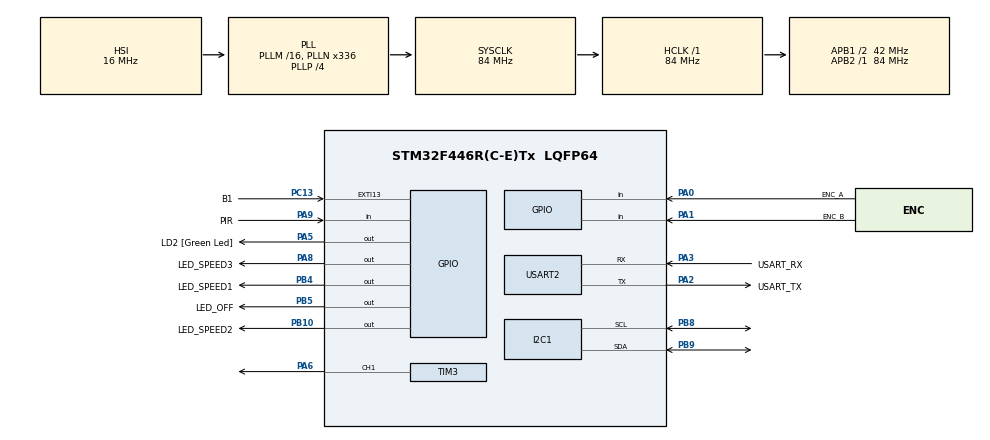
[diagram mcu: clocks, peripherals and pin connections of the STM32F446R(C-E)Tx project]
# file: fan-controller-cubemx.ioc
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Dma.Request0=USART2_TX
Dma.USART2_TX.0.Direction=DMA_MEMORY_TO_PERIPH
Dma.USART2_TX.0.FIFOMode=DMA_FIFOMODE_DISABLE
Dma.USART2_TX.0.Instance=DMA1_Stream6
Dma.USART2_TX.0.MemDataAlignment=DMA_MDATAALIGN_BYTE
Dma.USART2_TX.0.MemInc=DMA_MINC_ENABLE
Dma.USART2_TX.0.Mode=DMA_NORMAL
Dma.USART2_TX.0.PeriphDataAlignment=DMA_PDATAALIGN_BYTE
Dma.USART2_TX.0.PeriphInc=DMA_PINC_DISABLE
Dma.USART2_TX.0.Priority=DMA_PRIORITY_LOW
FREERTOS.Tasks01=defaultTask,24,128,StartDefaultTask,Default,NULL,Dynamic,NULL,NULL
FREERTOS.configUSE_NEWLIB_REENTRANT=1
Mcu.Family=STM32F4
Mcu.Name=STM32F446R(C-E)Tx
Mcu.Package=LQFP64
NVIC.DMA1_Stream6_IRQn=true\:5\:0\:false\:false\:true\:true\:false\:true\:true
NVIC.EXTI15_10_IRQn=true\:5\:0\:false\:false\:true\:true\:true\:true\:true
NVIC.PriorityGroup=NVIC_PRIORITYGROUP_4
NVIC.TIM1_TRG_COM_TIM11_IRQn=true\:15\:0\:false\:false\:true\:false\:false\:true\:true
NVIC.TIM2_IRQn=true\:5\:0\:false\:false\:true\:true\:true\:true\:true
NVIC.TimeBase=TIM1_TRG_COM_TIM11_IRQn
NVIC.TimeBaseIP=TIM11
NVIC.USART2_IRQn=true\:5\:0\:false\:false\:true\:true\:true\:true\:true
PA0-WKUP.GPIO_Label=ENC_A
PA0-WKUP.GPIO_PuPd=GPIO_PULLUP
PA0-WKUP.Signal=GPIO_Input
PA1.GPIO_Label=ENC_B
PA1.GPIO_PuPd=GPIO_PULLUP
PA1.Signal=GPIO_Input
PA13.Signal=SYS_JTMS-SWDIO
PA14.GPIO_Label=TCK
PA14.Signal=SYS_JTCK-SWCLK
PA2.GPIO_Label=USART_TX
PA2.Mode=Asynchronous
PA2.Signal=USART2_TX
PA3.GPIO_Label=USART_RX
PA3.Mode=Asynchronous
PA3.Signal=USART2_RX
PA5.GPIO_Label=LD2 [Green Led]
PA5.Signal=GPIO_Output
PA6.Signal=S_TIM3_CH1
PA8.GPIO_Label=LED_SPEED3
PA8.Signal=GPIO_Output
PA9.GPIO_Label=PIR
PA9.GPIO_PuPd=GPIO_PULLDOWN
PA9.Signal=GPIO_Input
PB10.GPIO_Label=LED_SPEED2
PB10.Signal=GPIO_Output
PB3.GPIO_Label=SWO
PB3.Signal=SYS_JTDO-SWO
PB4.GPIO_Label=LED_SPEED1
PB4.Signal=GPIO_Output
PB5.GPIO_Label=LED_OFF
PB5.Signal=GPIO_Output
PB8.Mode=I2C
PB8.Signal=I2C1_SCL
PB9.Mode=I2C
PB9.Signal=I2C1_SDA
PC13.GPIO_Label=B1
PC13.Signal=GPXTI13
PC14-OSC32_IN.Mode=LSE-External-Oscillator
PC14-OSC32_IN.Signal=RCC_OSC32_IN
PC15-OSC32_OUT.Mode=LSE-External-Oscillator
PC15-OSC32_OUT.Signal=RCC_OSC32_OUT
PH0-OSC_IN.Mode=HSE-External-Oscillator
PH0-OSC_IN.Signal=RCC_OSC_IN
PH1-OSC_OUT.Mode=HSE-External-Oscillator
PH1-OSC_OUT.Signal=RCC_OSC_OUT
ProjectManager.HeapSize=0x200
ProjectManager.StackSize=0x400
ProjectManager.TargetToolchain=STM32CubeIDE
RCC.48MHZClocksFreq_Value=84000000
RCC.AHBFreq_Value=84000000
RCC.APB1CLKDivider=RCC_HCLK_DIV2
RCC.APB1Freq_Value=42000000
RCC.APB1TimFreq_Value=84000000
RCC.APB2Freq_Value=84000000
RCC.APB2TimFreq_Value=84000000
RCC.CortexFreq_Value=84000000
RCC.FLatency-AdvancedSettings=FLASH_LATENCY_2
RCC.HCLKFreq_Value=84000000
RCC.HSE_VALUE=8000000
RCC.HSI_VALUE=16000000
RCC.PLLN=336
RCC.PLLP=RCC_PLLP_DIV4
RCC.SYSCLKFreq_VALUE=84000000
RCC.SYSCLKSource=RCC_SYSCLKSOURCE_PLLCLK
RCC.USBFreq_Value=168000000
RCC.VCOOutputFreq_Value=336000000
SH.S_TIM3_CH1.0=TIM3_CH1,PWM Generation1 CH1
TIM2.Period=999
TIM2.Prescaler=83
TIM3.Channel-PWM\ Generation1\ CH1=TIM_CHANNEL_1
TIM3.Period=999
TIM3.Prescaler=83
USART2.VirtualMode=VM_ASYNC
VP_FREERTOS_VS_CMSIS_V2.Mode=CMSIS_V2
VP_SYS_VS_tim11.Mode=TIM11
VP_TIM2_VS_ClockSourceINT.Mode=Internal
board=NUCLEO-F446RE

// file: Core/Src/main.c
/* USER CODE BEGIN Header */
/**
  ******************************************************************************
  * @file           : main.c
  * @brief          : Main program body
  ******************************************************************************
  * @attention
  *
  * Copyright (c) 2026 STMicroelectronics.
  * All rights reserved.
  *
  * This software is licensed under terms that can be found in the LICENSE file
  * in the root directory of this software component.
  * If no LICENSE file comes with this software, it is provided AS-IS.
  *
  ******************************************************************************
  */
/* USER CODE END Header */
#include "main.h"
#include "cmsis_os.h"

/* USER CODE BEGIN Includes */
#include "app.h"
#include "rt_measure.h"
/* USER CODE END Includes */

I2C_HandleTypeDef hi2c1;

TIM_HandleTypeDef htim2;
TIM_HandleTypeDef htim3;

UART_HandleTypeDef huart2;
DMA_HandleTypeDef hdma_usart2_tx;

/* Definitions for defaultTask */
osThreadId_t defaultTaskHandle;
const osThreadAttr_t defaultTask_attributes = {
  .name = "defaultTask",
  .stack_size = 128 * 4,
  .priority = (osPriority_t) osPriorityNormal,
};

void SystemClock_Config(void);
static void MX_GPIO_Init(void);
static void MX_DMA_Init(void);
static void MX_USART2_UART_Init(void);
static void MX_TIM3_Init(void);
static void MX_TIM2_Init(void);
static void MX_I2C1_Init(void);
void StartDefaultTask(void *argument);

int main(void)
{

  /* MCU Configuration--------------------------------------------------------*/

  /* Reset of all peripherals, Initializes the Flash interface and the Systick. */
  HAL_Init();

  /* Configure the system clock */
  SystemClock_Config();

  /* Initialize all configured peripherals */
  MX_GPIO_Init();
  MX_DMA_Init();
  MX_USART2_UART_Init();
  MX_TIM3_Init();
  MX_TIM2_Init();
  MX_I2C1_Init();

  /* Init scheduler */
  osKernelInitialize();

  /* Create the thread(s) */
  /* creation of defaultTask */
  defaultTaskHandle = osThreadNew(StartDefaultTask, NULL, &defaultTask_attributes);

  /* USER CODE BEGIN RTOS_THREADS */
  if (!App_CreateTasks())
  {
    Error_Handler();
  }
  /* USER CODE END RTOS_THREADS */

  /* USER CODE BEGIN RTOS_EVENTS */
  App_QueueStartupLog();
  /* USER CODE END RTOS_EVENTS */

  /* Start scheduler */
  osKernelStart();

  /* We should never get here as control is now taken by the scheduler */

  /* Infinite loop */
  while (1)
  {

  }
}

void SystemClock_Config(void)
{
  RCC_OscInitTypeDef RCC_OscInitStruct = {0};
  RCC_ClkInitTypeDef RCC_ClkInitStruct = {0};

  /** Configure the main internal regulator output voltage
  */
  __HAL_RCC_PWR_CLK_ENABLE();
  __HAL_PWR_VOLTAGESCALING_CONFIG(PWR_REGULATOR_VOLTAGE_SCALE3);

  /** Initializes the RCC Oscillators according to the specified parameters
  * in the RCC_OscInitTypeDef structure.
  */
  RCC_OscInitStruct.OscillatorType = RCC_OSCILLATORTYPE_HSI;
  RCC_OscInitStruct.HSIState = RCC_HSI_ON;
  RCC_OscInitStruct.HSICalibrationValue = RCC_HSICALIBRATION_DEFAULT;
  RCC_OscInitStruct.PLL.PLLState = RCC_PLL_ON;
  RCC_OscInitStruct.PLL.PLLSource = RCC_PLLSOURCE_HSI;
  RCC_OscInitStruct.PLL.PLLM = 16;
  RCC_OscInitStruct.PLL.PLLN = 336;
  RCC_OscInitStruct.PLL.PLLP = RCC_PLLP_DIV4;
  RCC_OscInitStruct.PLL.PLLQ = 2;
  RCC_OscInitStruct.PLL.PLLR = 2;
  if (HAL_RCC_OscConfig(&RCC_OscInitStruct) != HAL_OK)
  {
    Error_Handler();
  }

  /** Initializes the CPU, AHB and APB buses clocks
  */
  RCC_ClkInitStruct.ClockType = RCC_CLOCKTYPE_HCLK|RCC_CLOCKTYPE_SYSCLK
                              |RCC_CLOCKTYPE_PCLK1|RCC_CLOCKTYPE_PCLK2;
  RCC_ClkInitStruct.SYSCLKSource = RCC_SYSCLKSOURCE_PLLCLK;
  RCC_ClkInitStruct.AHBCLKDivider = RCC_SYSCLK_DIV1;
  RCC_ClkInitStruct.APB1CLKDivider = RCC_HCLK_DIV2;
  RCC_ClkInitStruct.APB2CLKDivider = RCC_HCLK_DIV1;

  if (HAL_RCC_ClockConfig(&RCC_ClkInitStruct, FLASH_LATENCY_2) != HAL_OK)
  {
    Error_Handler();
  }
}

static void MX_I2C1_Init(void)
{

  hi2c1.Instance = I2C1;
  hi2c1.Init.ClockSpeed = 100000;
  hi2c1.Init.DutyCycle = I2C_DUTYCYCLE_2;
  hi2c1.Init.OwnAddress1 = 0;
  hi2c1.Init.AddressingMode = I2C_ADDRESSINGMODE_7BIT;
  hi2c1.Init.DualAddressMode = I2C_DUALADDRESS_DISABLE;
  hi2c1.Init.OwnAddress2 = 0;
  hi2c1.Init.GeneralCallMode = I2C_GENERALCALL_DISABLE;
  hi2c1.Init.NoStretchMode = I2C_NOSTRETCH_DISABLE;
  if (HAL_I2C_Init(&hi2c1) != HAL_OK)
  {
    Error_Handler();
  }

}

static void MX_TIM2_Init(void)
{

  TIM_ClockConfigTypeDef sClockSourceConfig = {0};
  TIM_MasterConfigTypeDef sMasterConfig = {0};

  htim2.Instance = TIM2;
  htim2.Init.Prescaler = 83;
  htim2.Init.CounterMode = TIM_COUNTERMODE_UP;
  htim2.Init.Period = 999;
  htim2.Init.ClockDivision = TIM_CLOCKDIVISION_DIV1;
  htim2.Init.AutoReloadPreload = TIM_AUTORELOAD_PRELOAD_DISABLE;
  if (HAL_TIM_Base_Init(&htim2) != HAL_OK)
  {
    Error_Handler();
  }
  sClockSourceConfig.ClockSource = TIM_CLOCKSOURCE_INTERNAL;
  if (HAL_TIM_ConfigClockSource(&htim2, &sClockSourceConfig) != HAL_OK)
  {
    Error_Handler();
  }
  sMasterConfig.MasterOutputTrigger = TIM_TRGO_RESET;
  sMasterConfig.MasterSlaveMode = TIM_MASTERSLAVEMODE_DISABLE;
  if (HAL_TIMEx_MasterConfigSynchronization(&htim2, &sMasterConfig) != HAL_OK)
  {
    Error_Handler();
  }

}

static void MX_TIM3_Init(void)
{

  TIM_MasterConfigTypeDef sMasterConfig = {0};
  TIM_OC_InitTypeDef sConfigOC = {0};

  htim3.Instance = TIM3;
  htim3.Init.Prescaler = 83;
  htim3.Init.CounterMode = TIM_COUNTERMODE_UP;
  htim3.Init.Period = 999;
  htim3.Init.ClockDivision = TIM_CLOCKDIVISION_DIV1;
  htim3.Init.AutoReloadPreload = TIM_AUTORELOAD_PRELOAD_DISABLE;
  if (HAL_TIM_PWM_Init(&htim3) != HAL_OK)
  {
    Error_Handler();
  }
  sMasterConfig.MasterOutputTrigger = TIM_TRGO_RESET;
  sMasterConfig.MasterSlaveMode = TIM_MASTERSLAVEMODE_DISABLE;
  if (HAL_TIMEx_MasterConfigSynchronization(&htim3, &sMasterConfig) != HAL_OK)
  {
    Error_Handler();
  }
  sConfigOC.OCMode = TIM_OCMODE_PWM1;
  sConfigOC.Pulse = 0;
  sConfigOC.OCPolarity = TIM_OCPOLARITY_HIGH;
  sConfigOC.OCFastMode = TIM_OCFAST_DISABLE;
  if (HAL_TIM_PWM_ConfigChannel(&htim3, &sConfigOC, TIM_CHANNEL_1) != HAL_OK)
  {
    Error_Handler();
  }
  HAL_TIM_MspPostInit(&htim3);

}

static void MX_USART2_UART_Init(void)
{

  huart2.Instance = USART2;
  huart2.Init.BaudRate = 115200;
  huart2.Init.WordLength = UART_WORDLENGTH_8B;
  huart2.Init.StopBits = UART_STOPBITS_1;
  huart2.Init.Parity = UART_PARITY_NONE;
  huart2.Init.Mode = UART_MODE_TX_RX;
  huart2.Init.HwFlowCtl = UART_HWCONTROL_NONE;
  huart2.Init.OverSampling = UART_OVERSAMPLING_16;
  if (HAL_UART_Init(&huart2) != HAL_OK)
  {
    Error_Handler();
  }

}

static void MX_DMA_Init(void)
{

  /* DMA controller clock enable */
  __HAL_RCC_DMA1_CLK_ENABLE();

  /* DMA interrupt init */
  /* DMA1_Stream6_IRQn interrupt configuration */
  HAL_NVIC_SetPriority(DMA1_Stream6_IRQn, 5, 0);
  HAL_NVIC_EnableIRQ(DMA1_Stream6_IRQn);

}

static void MX_GPIO_Init(void)
{
  GPIO_InitTypeDef GPIO_InitStruct = {0};

  /* GPIO Ports Clock Enable */
  __HAL_RCC_GPIOC_CLK_ENABLE();
  __HAL_RCC_GPIOH_CLK_ENABLE();
  __HAL_RCC_GPIOA_CLK_ENABLE();
  __HAL_RCC_GPIOB_CLK_ENABLE();

  /*Configure GPIO pin Output Level */
  HAL_GPIO_WritePin(GPIOA, LD2_Pin|LED_SPEED3_Pin, GPIO_PIN_RESET);

  /*Configure GPIO pin Output Level */
  HAL_GPIO_WritePin(GPIOB, LED_SPEED2_Pin|LED_SPEED1_Pin|LED_OFF_Pin, GPIO_PIN_RESET);

  /*Configure GPIO pin : B1_Pin */
  GPIO_InitStruct.Pin = B1_Pin;
  GPIO_InitStruct.Mode = GPIO_MODE_IT_RISING;
  GPIO_InitStruct.Pull = GPIO_NOPULL;
  HAL_GPIO_Init(B1_GPIO_Port, &GPIO_InitStruct);

  /*Configure GPIO pins : ENC_A_Pin ENC_B_Pin */
  GPIO_InitStruct.Pin = ENC_A_Pin|ENC_B_Pin;
  GPIO_InitStruct.Mode = GPIO_MODE_INPUT;
  GPIO_InitStruct.Pull = GPIO_PULLUP;
  HAL_GPIO_Init(GPIOA, &GPIO_InitStruct);

  /*Configure GPIO pins : LD2_Pin LED_SPEED3_Pin */
  GPIO_InitStruct.Pin = LD2_Pin|LED_SPEED3_Pin;
  GPIO_InitStruct.Mode = GPIO_MODE_OUTPUT_PP;
  GPIO_InitStruct.Pull = GPIO_NOPULL;
  GPIO_InitStruct.Speed = GPIO_SPEED_FREQ_LOW;
  HAL_GPIO_Init(GPIOA, &GPIO_InitStruct);

  /*Configure GPIO pins : LED_SPEED2_Pin LED_SPEED1_Pin LED_OFF_Pin */
  GPIO_InitStruct.Pin = LED_SPEED2_Pin|LED_SPEED1_Pin|LED_OFF_Pin;
  GPIO_InitStruct.Mode = GPIO_MODE_OUTPUT_PP;
  GPIO_InitStruct.Pull = GPIO_NOPULL;
  GPIO_InitStruct.Speed = GPIO_SPEED_FREQ_LOW;
  HAL_GPIO_Init(GPIOB, &GPIO_InitStruct);

  /*Configure GPIO pin : PIR_Pin */
  GPIO_InitStruct.Pin = PIR_Pin;
  GPIO_InitStruct.Mode = GPIO_MODE_INPUT;
  GPIO_InitStruct.Pull = GPIO_PULLDOWN;
  HAL_GPIO_Init(PIR_GPIO_Port, &GPIO_InitStruct);

  /* EXTI interrupt init*/
  HAL_NVIC_SetPriority(EXTI15_10_IRQn, 5, 0);
  HAL_NVIC_EnableIRQ(EXTI15_10_IRQn);

}

void StartDefaultTask(void *argument)
{
  for(;;)
  {
    osDelay(1);
  }
}

void HAL_TIM_PeriodElapsedCallback(TIM_HandleTypeDef *htim)
{
  if (htim->Instance == TIM11)
  {
    HAL_IncTick();
  }
  /* USER CODE BEGIN Callback 1 */
  if (htim->Instance == TIM2)
  {
    RtMeasure_TimerElapsedFromISR(htim);
  }

  /* USER CODE END Callback 1 */
}

void Error_Handler(void)
{
  __disable_irq();
  while (1)
  {
  }
}
